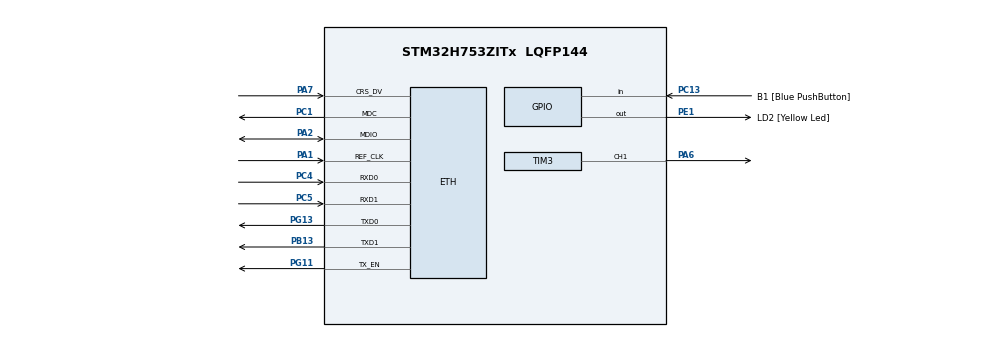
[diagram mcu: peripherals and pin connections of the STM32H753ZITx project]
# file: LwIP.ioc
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CORTEX_M7.AccessPermission_S-Cortex_Memory_Protection_Unit_Region1_Settings_S=MPU_REGION_FULL_ACCESS
CORTEX_M7.AccessPermission_S-Cortex_Memory_Protection_Unit_Region2_Settings_S=MPU_REGION_FULL_ACCESS
CORTEX_M7.AccessPermission_Spec=MPU_REGION_NO_ACCESS
CORTEX_M7.BaseAddress_S-Cortex_Memory_Protection_Unit_Region1_Settings_S=0x30020000
CORTEX_M7.BaseAddress_S-Cortex_Memory_Protection_Unit_Region2_Settings_S=0x30040000
CORTEX_M7.CPU_DCache=Enabled
CORTEX_M7.CPU_ICache=Enabled
CORTEX_M7.DisableExec_S-Cortex_Memory_Protection_Unit_Region1_Settings_S=MPU_INSTRUCTION_ACCESS_DISABLE
CORTEX_M7.DisableExec_S-Cortex_Memory_Protection_Unit_Region2_Settings_S=MPU_INSTRUCTION_ACCESS_DISABLE
CORTEX_M7.Enable_S-Cortex_Memory_Protection_Unit_Region1_Settings_S=MPU_REGION_ENABLE
CORTEX_M7.Enable_S-Cortex_Memory_Protection_Unit_Region2_Settings_S=MPU_REGION_ENABLE
CORTEX_M7.IsBufferable_S-Cortex_Memory_Protection_Unit_Region2_Settings_S=MPU_ACCESS_BUFFERABLE
CORTEX_M7.IsShareable_S-Cortex_Memory_Protection_Unit_Region2_Settings_S=MPU_ACCESS_SHAREABLE
CORTEX_M7.MPU_Control=MPU_PRIVILEGED_DEFAULT
CORTEX_M7.Size_S-Cortex_Memory_Protection_Unit_Region1_Settings_S=MPU_REGION_SIZE_128KB
CORTEX_M7.Size_S-Cortex_Memory_Protection_Unit_Region2_Settings_S=MPU_REGION_SIZE_512B
CORTEX_M7.TypeExtField_S-Cortex_Memory_Protection_Unit_Region1_Settings_S=MPU_TEX_LEVEL1
CORTEX_M7.default_mode_Activation=1
ETH.MediaInterface=HAL_ETH_RMII_MODE
ETH.RxBuffLen=1536
ETH.RxDescAddress=0x30040000
ETH.TxDescAddress=0x30040200
FREERTOS.HEAP_NUMBER=4
FREERTOS.Tasks01=defaultTask,24,512,StartDefaultTask,Default,NULL,Dynamic,NULL,NULL
FREERTOS.configCHECK_FOR_STACK_OVERFLOW=1
FREERTOS.configMINIMAL_STACK_SIZE=512
FREERTOS.configTOTAL_HEAP_SIZE=30720
FREERTOS.configUSE_NEWLIB_REENTRANT=1
LWIP.BSP.number=1
LWIP.DEFAULT_THREAD_STACKSIZE=2048
LWIP.IP_ADDRESS=192.168.088.100
LWIP.LWIP_DHCP=1
LWIP.LWIP_HTTPD=1
LWIP.LWIP_RAM_HEAP_POINTER=0x30020000
LWIP.MEM_SIZE=131048
LWIP.NETMASK_ADDRESS=255.255.255.000
LWIP.TCPIP_THREAD_STACKSIZE=2048
LWIP.TCP_MSS=1460
LWIP.TCP_SND_BUF=5840
LWIP.TCP_SND_QUEUELEN=16
LWIP.TCP_WND=5840
LWIP.Version=v2.1.2_Cube
LWIP0.BSP.STBoard=false
LWIP0.BSP.api=BSP_COMPONENT_DRIVER
LWIP0.BSP.component=LAN8742
LWIP0.BSP.instance=LAN8742
LWIP0.BSP.name=Driver_PHY
LWIP0.BSP.semaphore=S_LAN8742
LWIP0.BSP.solution=LAN8742
Mcu.Family=STM32H7
Mcu.Name=STM32H753ZITx
Mcu.Package=LQFP144
NUCLEO-H753ZI.LD1=true
NUCLEO-H753ZI.LD2=false
NUCLEO-H753ZI.LD3=true
NVIC.ETH_IRQn=true\:5\:0\:false\:false\:true\:true\:true\:true\:true
NVIC.PriorityGroup=NVIC_PRIORITYGROUP_4
NVIC.TIM6_DAC_IRQn=true\:15\:0\:false\:false\:true\:false\:false\:true\:true
NVIC.TimeBase=TIM6_DAC_IRQn
NVIC.TimeBaseIP=TIM6
PA1.GPIO_Speed=GPIO_SPEED_FREQ_VERY_HIGH
PA1.Mode=RMII
PA1.Signal=ETH_REF_CLK
PA2.GPIO_Speed=GPIO_SPEED_FREQ_VERY_HIGH
PA2.Mode=RMII
PA2.Signal=ETH_MDIO
PA6.Signal=S_TIM3_CH1
PA7.GPIO_Speed=GPIO_SPEED_FREQ_VERY_HIGH
PA7.Mode=RMII
PA7.Signal=ETH_CRS_DV
PB13.GPIO_Speed=GPIO_SPEED_FREQ_VERY_HIGH
PB13.Mode=RMII
PB13.Signal=ETH_TXD1
PC1.GPIO_Speed=GPIO_SPEED_FREQ_VERY_HIGH
PC1.Mode=RMII
PC1.Signal=ETH_MDC
PC13.GPIO_Label=B1 [Blue PushButton]
PC13.Signal=GPIO_Input
PC14-OSC32_IN\ (OSC32_IN).Signal=RCC_OSC32_IN
PC15-OSC32_OUT\ (OSC32_OUT).Signal=RCC_OSC32_OUT
PC4.GPIO_Speed=GPIO_SPEED_FREQ_VERY_HIGH
PC4.Mode=RMII
PC4.Signal=ETH_RXD0
PC5.GPIO_Speed=GPIO_SPEED_FREQ_VERY_HIGH
PC5.Mode=RMII
PC5.Signal=ETH_RXD1
PD8.GPIO_Label=STLINK_RX
PD8.Signal=USART3_TX
PD9.GPIO_Label=STLINK_TX
PD9.Signal=USART3_RX
PE1.GPIO_Label=LD2 [Yellow Led]
PE1.Signal=GPIO_Output
PG11.GPIO_Speed=GPIO_SPEED_FREQ_VERY_HIGH
PG11.Mode=RMII
PG11.Signal=ETH_TX_EN
PG13.GPIO_Speed=GPIO_SPEED_FREQ_VERY_HIGH
PG13.Mode=RMII
PG13.Signal=ETH_TXD0
PH0-OSC_IN\ (PH0).Signal=RCC_OSC_IN
PH1-OSC_OUT\ (PH1).Signal=RCC_OSC_OUT
ProjectManager.HeapSize=0x200
ProjectManager.StackSize=0x400
ProjectManager.TargetToolchain=STM32CubeIDE
RCC.ADCFreq_Value=129000000
RCC.APB1Freq_Value=75000000
RCC.APB2Freq_Value=75000000
RCC.APB3Freq_Value=75000000
RCC.APB4Freq_Value=75000000
RCC.CortexFreq_Value=300000000
RCC.D1PPRE=RCC_APB3_DIV2
RCC.D2PPRE1=RCC_APB1_DIV2
RCC.D2PPRE2=RCC_APB2_DIV2
RCC.D3PPRE=RCC_APB4_DIV2
RCC.DIVM1=4
RCC.DIVN1=37
RCC.DIVQ1=4
RCC.HCLKFreq_Value=150000000
RCC.HPRE=RCC_HCLK_DIV2
RCC.HSE_VALUE=8000000
RCC.PLL2FRACN=0
RCC.PLL3FRACN=0
RCC.PLLFRACN=4096
RCC.PWR_Regulator_Voltage_Scale=PWR_REGULATOR_VOLTAGE_SCALE2
RCC.SYSCLKFreq_VALUE=300000000
RCC.SYSCLKSource=RCC_SYSCLKSOURCE_PLLCLK
RCC.USBFreq_Value=150000000
SH.S_TIM3_CH1.0=TIM3_CH1,PWM Generation1 CH1
TIM3.AutoReloadPreload=TIM_AUTORELOAD_PRELOAD_ENABLE
TIM3.Channel-PWM\ Generation1\ CH1=TIM_CHANNEL_1
TIM3.Period=65535-1
TIM3.Prescaler=50-1
TIM3.Pulse-PWM\ Generation1\ CH1=20
VP_FREERTOS_VS_CMSIS_V2.Mode=CMSIS_V2
VP_LWIP_VS_Enabled.Mode=Enabled
VP_MEMORYMAP_VS_MEMORYMAP.Mode=CurAppReg
VP_NUCLEO-H753ZI_VS_BSP_COMMON.Mode=COMMON
VP_SYS_VS_tim6.Mode=TIM6
VP_TIM3_VS_ClockSourceINT.Mode=Internal
board=NUCLEO-H753ZI

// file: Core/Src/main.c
/* USER CODE BEGIN Header */
/**
  ******************************************************************************
  * @file           : main.c
  * @brief          : Main program body
  ******************************************************************************
  * @attention
  *
  * Copyright (c) 2025 STMicroelectronics.
  * All rights reserved.
  *
  * This software is licensed under terms that can be found in the LICENSE file
  * in the root directory of this software component.
  * If no LICENSE file comes with this software, it is provided AS-IS.
  *
  ******************************************************************************
  */
/* USER CODE END Header */
#include "main.h"
#include "cmsis_os.h"
#include "lwip.h"

/* USER CODE BEGIN Includes */
/* ETH_CODE: add lwiperf, see comment in StartDefaultTask function */
#include "lwip/apps/lwiperf.h"
#include "lwip/netif.h"
#include "lwip/apps/httpd.h"
#include "httpserver.h"
/* USER CODE END Includes */

/* USER CODE BEGIN PTD */
extern struct netif gnetif;
/* USER CODE END PTD */

TIM_HandleTypeDef htim3;

/* Definitions for defaultTask */
osThreadId_t defaultTaskHandle;
const osThreadAttr_t defaultTask_attributes = {
  .name = "defaultTask",
  .stack_size = 512 * 4,
  .priority = (osPriority_t) osPriorityNormal,
};

void SystemClock_Config(void);
static void MPU_Config(void);
static void MX_GPIO_Init(void);
static void MX_TIM3_Init(void);
void StartDefaultTask(void *argument);

int main(void)
{

  /* MPU Configuration--------------------------------------------------------*/
  MPU_Config();

  /* Enable the CPU Cache */

  /* Enable I-Cache---------------------------------------------------------*/
  SCB_EnableICache();

  /* Enable D-Cache---------------------------------------------------------*/
  SCB_EnableDCache();

  /* MCU Configuration--------------------------------------------------------*/

  /* Reset of all peripherals, Initializes the Flash interface and the Systick. */
  HAL_Init();

  /* Configure the system clock */
  SystemClock_Config();

  /* Initialize all configured peripherals */
  MX_GPIO_Init();
  MX_TIM3_Init();

  /* Init scheduler */
  osKernelInitialize();

  /* Create the thread(s) */
  /* creation of defaultTask */
  defaultTaskHandle = osThreadNew(StartDefaultTask, NULL, &defaultTask_attributes);

  /* Initialize leds */
  BSP_LED_Init(LED_GREEN);
  BSP_LED_Init(LED_RED);

  /* Start scheduler */
  osKernelStart();

  /* We should never get here as control is now taken by the scheduler */

  /* Infinite loop */
  while (1)
  {

  }
}

void SystemClock_Config(void)
{
  RCC_OscInitTypeDef RCC_OscInitStruct = {0};
  RCC_ClkInitTypeDef RCC_ClkInitStruct = {0};

  /** Supply configuration update enable
  */
  HAL_PWREx_ConfigSupply(PWR_LDO_SUPPLY);

  /** Configure the main internal regulator output voltage
  */
  __HAL_PWR_VOLTAGESCALING_CONFIG(PWR_REGULATOR_VOLTAGE_SCALE2);

  while(!__HAL_PWR_GET_FLAG(PWR_FLAG_VOSRDY)) {}

  /** Initializes the RCC Oscillators according to the specified parameters
  * in the RCC_OscInitTypeDef structure.
  */
  RCC_OscInitStruct.OscillatorType = RCC_OSCILLATORTYPE_HSI;
  RCC_OscInitStruct.HSIState = RCC_HSI_DIV1;
  RCC_OscInitStruct.HSICalibrationValue = RCC_HSICALIBRATION_DEFAULT;
  RCC_OscInitStruct.PLL.PLLState = RCC_PLL_ON;
  RCC_OscInitStruct.PLL.PLLSource = RCC_PLLSOURCE_HSI;
  RCC_OscInitStruct.PLL.PLLM = 4;
  RCC_OscInitStruct.PLL.PLLN = 37;
  RCC_OscInitStruct.PLL.PLLP = 2;
  RCC_OscInitStruct.PLL.PLLQ = 4;
  RCC_OscInitStruct.PLL.PLLR = 2;
  RCC_OscInitStruct.PLL.PLLRGE = RCC_PLL1VCIRANGE_3;
  RCC_OscInitStruct.PLL.PLLVCOSEL = RCC_PLL1VCOWIDE;
  RCC_OscInitStruct.PLL.PLLFRACN = 4096;
  if (HAL_RCC_OscConfig(&RCC_OscInitStruct) != HAL_OK)
  {
    Error_Handler();
  }

  /** Initializes the CPU, AHB and APB buses clocks
  */
  RCC_ClkInitStruct.ClockType = RCC_CLOCKTYPE_HCLK|RCC_CLOCKTYPE_SYSCLK
                              |RCC_CLOCKTYPE_PCLK1|RCC_CLOCKTYPE_PCLK2
                              |RCC_CLOCKTYPE_D3PCLK1|RCC_CLOCKTYPE_D1PCLK1;
  RCC_ClkInitStruct.SYSCLKSource = RCC_SYSCLKSOURCE_PLLCLK;
  RCC_ClkInitStruct.SYSCLKDivider = RCC_SYSCLK_DIV1;
  RCC_ClkInitStruct.AHBCLKDivider = RCC_HCLK_DIV2;
  RCC_ClkInitStruct.APB3CLKDivider = RCC_APB3_DIV2;
  RCC_ClkInitStruct.APB1CLKDivider = RCC_APB1_DIV2;
  RCC_ClkInitStruct.APB2CLKDivider = RCC_APB2_DIV2;
  RCC_ClkInitStruct.APB4CLKDivider = RCC_APB4_DIV2;

  if (HAL_RCC_ClockConfig(&RCC_ClkInitStruct, FLASH_LATENCY_2) != HAL_OK)
  {
    Error_Handler();
  }
}

static void MX_TIM3_Init(void)
{

  TIM_ClockConfigTypeDef sClockSourceConfig = {0};
  TIM_MasterConfigTypeDef sMasterConfig = {0};
  TIM_OC_InitTypeDef sConfigOC = {0};

  htim3.Instance = TIM3;
  htim3.Init.Prescaler = 50-1;
  htim3.Init.CounterMode = TIM_COUNTERMODE_UP;
  htim3.Init.Period = 65535-1;
  htim3.Init.ClockDivision = TIM_CLOCKDIVISION_DIV1;
  htim3.Init.AutoReloadPreload = TIM_AUTORELOAD_PRELOAD_ENABLE;
  if (HAL_TIM_Base_Init(&htim3) != HAL_OK)
  {
    Error_Handler();
  }
  sClockSourceConfig.ClockSource = TIM_CLOCKSOURCE_INTERNAL;
  if (HAL_TIM_ConfigClockSource(&htim3, &sClockSourceConfig) != HAL_OK)
  {
    Error_Handler();
  }
  if (HAL_TIM_PWM_Init(&htim3) != HAL_OK)
  {
    Error_Handler();
  }
  sMasterConfig.MasterOutputTrigger = TIM_TRGO_RESET;
  sMasterConfig.MasterSlaveMode = TIM_MASTERSLAVEMODE_DISABLE;
  if (HAL_TIMEx_MasterConfigSynchronization(&htim3, &sMasterConfig) != HAL_OK)
  {
    Error_Handler();
  }
  sConfigOC.OCMode = TIM_OCMODE_PWM1;
  sConfigOC.Pulse = 20;
  sConfigOC.OCPolarity = TIM_OCPOLARITY_HIGH;
  sConfigOC.OCFastMode = TIM_OCFAST_DISABLE;
  if (HAL_TIM_PWM_ConfigChannel(&htim3, &sConfigOC, TIM_CHANNEL_1) != HAL_OK)
  {
    Error_Handler();
  }
  HAL_TIM_MspPostInit(&htim3);

}

static void MX_GPIO_Init(void)
{
  GPIO_InitTypeDef GPIO_InitStruct = {0};

  /* GPIO Ports Clock Enable */
  __HAL_RCC_GPIOC_CLK_ENABLE();
  __HAL_RCC_GPIOH_CLK_ENABLE();
  __HAL_RCC_GPIOA_CLK_ENABLE();
  __HAL_RCC_GPIOB_CLK_ENABLE();
  __HAL_RCC_GPIOD_CLK_ENABLE();
  __HAL_RCC_GPIOG_CLK_ENABLE();
  __HAL_RCC_GPIOE_CLK_ENABLE();

  /*Configure GPIO pin Output Level */
  HAL_GPIO_WritePin(LD2_GPIO_Port, LD2_Pin, GPIO_PIN_RESET);

  /*Configure GPIO pin : B1_Pin */
  GPIO_InitStruct.Pin = B1_Pin;
  GPIO_InitStruct.Mode = GPIO_MODE_INPUT;
  GPIO_InitStruct.Pull = GPIO_NOPULL;
  HAL_GPIO_Init(B1_GPIO_Port, &GPIO_InitStruct);

  /*Configure GPIO pins : STLINK_RX_Pin STLINK_TX_Pin */
  GPIO_InitStruct.Pin = STLINK_RX_Pin|STLINK_TX_Pin;
  GPIO_InitStruct.Mode = GPIO_MODE_AF_PP;
  GPIO_InitStruct.Pull = GPIO_NOPULL;
  GPIO_InitStruct.Speed = GPIO_SPEED_FREQ_LOW;
  GPIO_InitStruct.Alternate = GPIO_AF7_USART3;
  HAL_GPIO_Init(GPIOD, &GPIO_InitStruct);

  /*Configure GPIO pin : LD2_Pin */
  GPIO_InitStruct.Pin = LD2_Pin;
  GPIO_InitStruct.Mode = GPIO_MODE_OUTPUT_PP;
  GPIO_InitStruct.Pull = GPIO_NOPULL;
  GPIO_InitStruct.Speed = GPIO_SPEED_FREQ_LOW;
  HAL_GPIO_Init(LD2_GPIO_Port, &GPIO_InitStruct);

}

void StartDefaultTask(void *argument)
{
  /* init code for LWIP */
  MX_LWIP_Init();
  /* USER CODE BEGIN 5 */
  //********************  IMPORTANT  ********************
  //tcpip_init() este apelat deja in MX_LWIP_Init()
  http_server_init();
  /* Infinite loop */
  for(;;)
  {
	if (netif_is_up(&gnetif)) {
	        BSP_LED_On(LED_GREEN);
	        BSP_LED_Off(LED_RED);
	      } else {
	        BSP_LED_On(LED_RED);
	        BSP_LED_Off(LED_GREEN);
	      }
    osDelay(1000);
  }
  /* USER CODE END 5 */
}

 /* MPU Configuration */

void MPU_Config(void)
{
  MPU_Region_InitTypeDef MPU_InitStruct = {0};

  /* Disables the MPU */
  HAL_MPU_Disable();

  /** Initializes and configures the Region and the memory to be protected
  */
  MPU_InitStruct.Enable = MPU_REGION_ENABLE;
  MPU_InitStruct.Number = MPU_REGION_NUMBER0;
  MPU_InitStruct.BaseAddress = 0x0;
  MPU_InitStruct.Size = MPU_REGION_SIZE_4GB;
  MPU_InitStruct.SubRegionDisable = 0x87;
  MPU_InitStruct.TypeExtField = MPU_TEX_LEVEL0;
  MPU_InitStruct.AccessPermission = MPU_REGION_NO_ACCESS;
  MPU_InitStruct.DisableExec = MPU_INSTRUCTION_ACCESS_DISABLE;
  MPU_InitStruct.IsShareable = MPU_ACCESS_SHAREABLE;
  MPU_InitStruct.IsCacheable = MPU_ACCESS_NOT_CACHEABLE;
  MPU_InitStruct.IsBufferable = MPU_ACCESS_NOT_BUFFERABLE;

  HAL_MPU_ConfigRegion(&MPU_InitStruct);

  /** Initializes and configures the Region and the memory to be protected
  */
  MPU_InitStruct.Number = MPU_REGION_NUMBER1;
  MPU_InitStruct.BaseAddress = 0x30020000;
  MPU_InitStruct.Size = MPU_REGION_SIZE_128KB;
  MPU_InitStruct.SubRegionDisable = 0x0;
  MPU_InitStruct.TypeExtField = MPU_TEX_LEVEL1;
  MPU_InitStruct.AccessPermission = MPU_REGION_FULL_ACCESS;
  MPU_InitStruct.IsShareable = MPU_ACCESS_NOT_SHAREABLE;

  HAL_MPU_ConfigRegion(&MPU_InitStruct);

  /** Initializes and configures the Region and the memory to be protected
  */
  MPU_InitStruct.Number = MPU_REGION_NUMBER2;
  MPU_InitStruct.BaseAddress = 0x30040000;
  MPU_InitStruct.Size = MPU_REGION_SIZE_512B;
  MPU_InitStruct.TypeExtField = MPU_TEX_LEVEL0;
  MPU_InitStruct.IsShareable = MPU_ACCESS_SHAREABLE;
  MPU_InitStruct.IsBufferable = MPU_ACCESS_BUFFERABLE;

  HAL_MPU_ConfigRegion(&MPU_InitStruct);
  /* Enables the MPU */
  HAL_MPU_Enable(MPU_PRIVILEGED_DEFAULT);

}

void HAL_TIM_PeriodElapsedCallback(TIM_HandleTypeDef *htim)
{
  if (htim->Instance == TIM6) {
    HAL_IncTick();
  }
}

void Error_Handler(void)
{
  __disable_irq();
  while (1)
  {
  }
}
